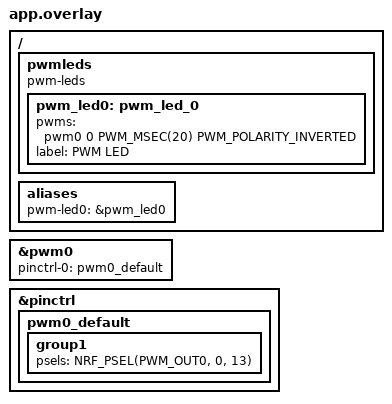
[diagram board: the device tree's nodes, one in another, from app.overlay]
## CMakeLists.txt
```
cmake_minimum_required(VERSION 3.13.1)
find_package(Zephyr REQUIRED HINTS $ENV{ZEPHYR_BASE})
project(2026-06-05_PWM_LED_Dimming)

target_sources(app PRIVATE src/main.c)
```

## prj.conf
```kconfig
CONFIG_PWM=y
CONFIG_LOG=y
CONFIG_LOG_DEFAULT_LEVEL=3
CONFIG_COMMON_LIBC_MALLOC_ARENA_SIZE=0
```

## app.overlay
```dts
/*
 * PWM output on LED1 (P0.13) of the nRF52840 DK.
 * Change the pin in pwm0_default to target a different GPIO.
 */
/ {
	pwmleds {
		compatible = "pwm-leds";
		pwm_led0: pwm_led_0 {
			pwms = <&pwm0 0 PWM_MSEC(20) PWM_POLARITY_INVERTED>;
			label = "PWM LED";
		};
	};

	aliases {
		pwm-led0 = &pwm_led0;
	};
};

&pwm0 {
	status = "okay";
	pinctrl-0 = <&pwm0_default>;
	pinctrl-names = "default";
};

&pinctrl {
	pwm0_default: pwm0_default {
		group1 {
			/* LED1 on nRF52840 DK = P0.13 (active-low, hence INVERTED) */
			psels = <NRF_PSEL(PWM_OUT0, 0, 13)>;
		};
	};
};
```

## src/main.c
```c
#include <zephyr/kernel.h>
#include <zephyr/drivers/pwm.h>
#include <zephyr/logging/log.h>

LOG_MODULE_REGISTER(day21, LOG_LEVEL_INF);

static const struct pwm_dt_spec pwm_led =
    PWM_DT_SPEC_GET(DT_ALIAS(pwm_led0));

#define STEPS      50
#define STEP_MS    20

int main(void)
{
    if (!pwm_is_ready_dt(&pwm_led)) {
        LOG_ERR("Day 21: PWM device not ready");
        return;
    }

    LOG_INF("Day 21: PWM breathing on LED1 (period=%u ns)", pwm_led.period);

    uint32_t period = pwm_led.period;
    uint32_t step   = period / STEPS;

    while (1) {
        /* Fade in */
        for (uint32_t pulse = 0; pulse <= period; pulse += step) {
            pwm_set_dt(&pwm_led, period, pulse);
            k_msleep(STEP_MS);
        }
        /* Fade out */
        for (uint32_t pulse = period; pulse > 0; pulse -= step) {
            pwm_set_dt(&pwm_led, period, pulse);
            k_msleep(STEP_MS);
        }
    }
    return 0;
}
```
